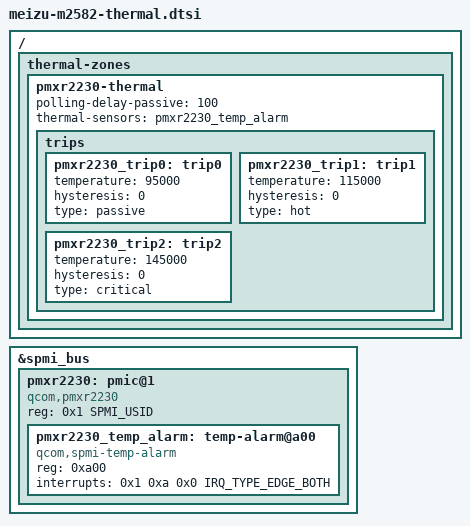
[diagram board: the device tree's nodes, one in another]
// SPDX-License-Identifier: BSD-3-Clause
/*
 * Meizu 22 (M2582) -- PMXR2230 over-temperature protection.
 *
 * The PMXR2230 supplies the CPU rails and watches its own die temperature in
 * hardware: stage 2 and stage 3 shutdown are armed by default, so it shuts
 * the board down on its own with Linux out of the loop. That is the one heat
 * limit available here -- TSENS calibration lives in efuse the non-secure
 * world cannot read, and throttling on an untrustworthy CPU temperature is
 * worse than not throttling.
 *
 * Trip points are the factory tree's values for this PMIC (95 C passive,
 * 115 C hot, 145 C critical), which match the binding's example for this
 * family. Software only ever lowers the hardware stage limits.
 */
&spmi_bus {
	pmxr2230: pmic@1 {
		compatible = "qcom,pmxr2230", "qcom,spmi-pmic";
		reg = <0x1 SPMI_USID>;
		#address-cells = <1>;
		#size-cells = <0>;

		pmxr2230_temp_alarm: temp-alarm@a00 {
			compatible = "qcom,spmi-temp-alarm";
			reg = <0xa00>;
			interrupts = <0x1 0xa 0x0 IRQ_TYPE_EDGE_BOTH>;
			#thermal-sensor-cells = <0>;
		};
	};
};

/ {
	thermal-zones {
		pmxr2230-thermal {
			polling-delay-passive = <100>;

			thermal-sensors = <&pmxr2230_temp_alarm>;

			trips {
				pmxr2230_trip0: trip0 {
					temperature = <95000>;
					hysteresis = <0>;
					type = "passive";
				};

				pmxr2230_trip1: trip1 {
					temperature = <115000>;
					hysteresis = <0>;
					type = "hot";
				};

				pmxr2230_trip2: trip2 {
					temperature = <145000>;
					hysteresis = <0>;
					type = "critical";
				};
			};
		};
	};
};
